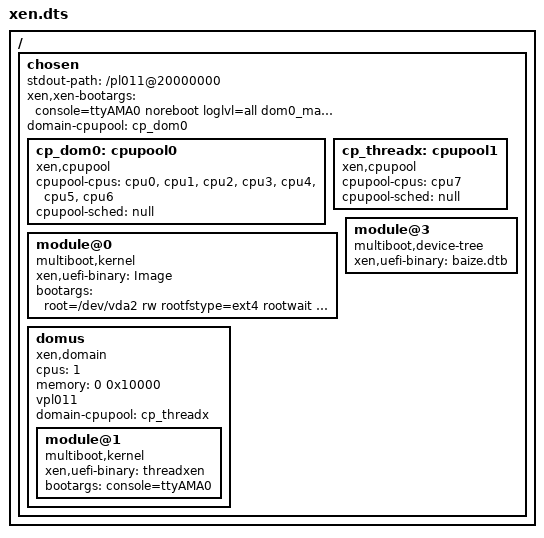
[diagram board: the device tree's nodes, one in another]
/dts-v1/;

/include/ "fake.dtsi"

/ {
	chosen {
		stdout-path = "/pl011@20000000";
		/* xen */
		xen,xen-bootargs = "console=ttyAMA0 noreboot loglvl=all dom0_max_vcpus=2 dom0_vcpus_pin dom0_mem=512M";
		#address-cells = <2>;
		#size-cells = <2>;

		/* begin of dom0-dtb */
		domain-cpupool = <&cp_dom0>;

		cp_dom0: cpupool0 {
			compatible = "xen,cpupool";
			cpupool-cpus = <&cpu0 &cpu1 &cpu2 &cpu3 &cpu4 &cpu5 &cpu6>;
			cpupool-sched = "null";
		};

		cp_threadx: cpupool1 {
			compatible = "xen,cpupool";
			cpupool-cpus = <&cpu7>;
			cpupool-sched = "null";
		};

		module@0 {
			/* compatible = "xen,linux-zimage","xen,multiboot-module"; */
			/* reg = <0x30000000 0xfe0000>; */
			compatible = "multiboot,kernel", "multiboot,module";
			xen,uefi-binary = "Image";
			bootargs = "root=/dev/vda2 rw rootfstype=ext4 rootwait earlycon console=ttyAMA0 init=/init ignore_loglevel";
		};

		module@3 {
			compatible = "multiboot,device-tree", "multiboot,module";
			xen,uefi-binary = "baize.dtb";
		};
		/* end of dom0-dtb */

		domus {
			compatible = "xen,domain";
			#address-cells = <2>;
			#size-cells = <2>;
			cpus = <1>;
			memory = <0 0x10000>;
			vpl011;
			domain-cpupool = <&cp_threadx>;

			module@1 {
				compatible = "multiboot,kernel", "multiboot,module";
				/* reg = <0x127a93000 0x1000000>; */
				xen,uefi-binary = "threadxen";
				bootargs = "console=ttyAMA0";
			};
		};
	};
};

